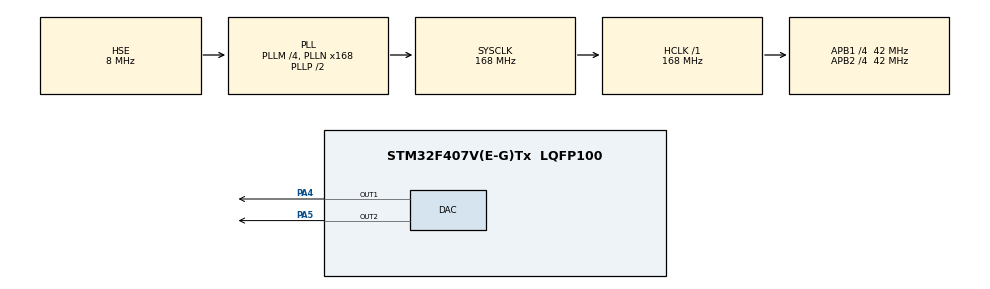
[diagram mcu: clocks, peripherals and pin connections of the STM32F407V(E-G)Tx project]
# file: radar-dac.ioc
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DAC.DAC_Trigger=DAC_TRIGGER_T2_TRGO
DAC.DAC_Trigger2=DAC_TRIGGER_T4_TRGO
DAC.TriangleAmplitude2=DAC_TRIANGLEAMPLITUDE_4095
DAC.WaveGeneration2=TriangleWaveGeneration
Dma.DAC1.0.Direction=DMA_MEMORY_TO_PERIPH
Dma.DAC1.0.FIFOMode=DMA_FIFOMODE_DISABLE
Dma.DAC1.0.Instance=DMA1_Stream5
Dma.DAC1.0.MemDataAlignment=DMA_MDATAALIGN_HALFWORD
Dma.DAC1.0.MemInc=DMA_MINC_ENABLE
Dma.DAC1.0.Mode=DMA_CIRCULAR
Dma.DAC1.0.PeriphDataAlignment=DMA_PDATAALIGN_HALFWORD
Dma.DAC1.0.PeriphInc=DMA_PINC_DISABLE
Dma.DAC1.0.Priority=DMA_PRIORITY_LOW
Dma.DAC2.1.Direction=DMA_MEMORY_TO_PERIPH
Dma.DAC2.1.FIFOMode=DMA_FIFOMODE_DISABLE
Dma.DAC2.1.Instance=DMA1_Stream6
Dma.DAC2.1.MemDataAlignment=DMA_MDATAALIGN_HALFWORD
Dma.DAC2.1.MemInc=DMA_MINC_ENABLE
Dma.DAC2.1.Mode=DMA_CIRCULAR
Dma.DAC2.1.PeriphDataAlignment=DMA_PDATAALIGN_HALFWORD
Dma.DAC2.1.PeriphInc=DMA_PINC_DISABLE
Dma.DAC2.1.Priority=DMA_PRIORITY_LOW
Dma.Request0=DAC1
Dma.Request1=DAC2
Mcu.Family=STM32F4
Mcu.Name=STM32F407V(E-G)Tx
Mcu.Package=LQFP100
NVIC.DMA1_Stream5_IRQn=true\:0\:0\:false\:false\:true\:false\:true\:true
NVIC.DMA1_Stream6_IRQn=true\:0\:0\:false\:false\:true\:false\:true\:true
NVIC.PriorityGroup=NVIC_PRIORITYGROUP_0
PA4.Signal=COMP_DAC1_group
PA5.Signal=COMP_DAC2_group
PH0-OSC_IN.Mode=HSE-External-Oscillator
PH0-OSC_IN.Signal=RCC_OSC_IN
PH1-OSC_OUT.Mode=HSE-External-Oscillator
PH1-OSC_OUT.Signal=RCC_OSC_OUT
ProjectManager.HeapSize=0x200
ProjectManager.StackSize=0x400
ProjectManager.TargetToolchain=STM32CubeIDE
RCC.48MHZClocksFreq_Value=48000000
RCC.AHBFreq_Value=168000000
RCC.APB1CLKDivider=RCC_HCLK_DIV4
RCC.APB1Freq_Value=42000000
RCC.APB1TimFreq_Value=84000000
RCC.APB2CLKDivider=RCC_HCLK_DIV4
RCC.APB2Freq_Value=42000000
RCC.APB2TimFreq_Value=84000000
RCC.CortexFreq_Value=168000000
RCC.HCLKFreq_Value=168000000
RCC.HSE_VALUE=8000000
RCC.HSI_VALUE=16000000
RCC.LSE_VALUE=32768
RCC.PLLM=4
RCC.PLLN=168
RCC.PLLQ=7
RCC.PLLSourceVirtual=RCC_PLLSOURCE_HSE
RCC.SYSCLKFreq_VALUE=168000000
RCC.SYSCLKSource=RCC_SYSCLKSOURCE_PLLCLK
RCC.VCOOutputFreq_Value=336000000
SH.COMP_DAC1_group.0=DAC_OUT1,DAC_OUT1
SH.COMP_DAC2_group.0=DAC_OUT2,DAC_OUT2
TIM2.Period=100-1
TIM2.Prescaler=84-1
TIM2.TIM_MasterOutputTrigger=TIM_TRGO_UPDATE
TIM4.Period=10-1
TIM4.Prescaler=84-1
TIM4.TIM_MasterOutputTrigger=TIM_TRGO_UPDATE
VP_TIM2_VS_ClockSourceINT.Mode=Internal
VP_TIM4_VS_ClockSourceINT.Mode=Internal
board=STM32F407G-DISC1

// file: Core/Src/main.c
/* USER CODE BEGIN Header */
/**
  ******************************************************************************
  * @file           : main.c
  * @brief          : Main program body
  ******************************************************************************
  * @attention
  *
  * Copyright (c) 2024 STMicroelectronics.
  * All rights reserved.
  *
  * This software is licensed under terms that can be found in the LICENSE file
  * in the root directory of this software component.
  * If no LICENSE file comes with this software, it is provided AS-IS.
  *
  ******************************************************************************
  */
/* USER CODE END Header */
#include "main.h"
#include "math.h"

DAC_HandleTypeDef hdac;
DMA_HandleTypeDef hdma_dac1;

TIM_HandleTypeDef htim2;
TIM_HandleTypeDef htim4;

void SystemClock_Config(void);
static void MX_GPIO_Init(void);
static void MX_DMA_Init(void);
static void MX_DAC_Init(void);
static void MX_TIM2_Init(void);
static void MX_TIM4_Init(void);

/* USER CODE BEGIN 0 */

float value = 0.2;
uint32_t var;
uint32_t sine_val[100];

#define PI 3.14159265358979323846

void calcsin ()
{
	for (int i=0; i<100; i++)
	{
		sine_val[i] = ((sin(i*2*PI/100) + 1)*(4096/2));
	}
}

/* USER CODE END 0 */

int main(void)
{

  /* MCU Configuration--------------------------------------------------------*/

  /* Reset of all peripherals, Initializes the Flash interface and the Systick. */
  HAL_Init();

  /* Configure the system clock */
  SystemClock_Config();

  /* Initialize all configured peripherals */
  MX_GPIO_Init();
  MX_DMA_Init();
  MX_DAC_Init();
  MX_TIM2_Init();
  MX_TIM4_Init();
  /* USER CODE BEGIN 2 */

  HAL_TIM_Base_Start(&htim4);
  HAL_DACEx_TriangleWaveGenerate(&hdac, DAC1_CHANNEL_2, DAC_TRIANGLEAMPLITUDE_2047);
  HAL_DAC_Start(&hdac, DAC1_CHANNEL_2);
  /* USER CODE END 2 */

  /* Infinite loop */
  while (1)
  {
	  HAL_TIM_Base_Start(&htim2);
	  calcsin();
	  HAL_DAC_Start_DMA(&hdac, DAC1_CHANNEL_1, sine_val, 100, DAC_ALIGN_12B_R);
  }
}

void SystemClock_Config(void)
{
  RCC_OscInitTypeDef RCC_OscInitStruct = {0};
  RCC_ClkInitTypeDef RCC_ClkInitStruct = {0};

  /** Configure the main internal regulator output voltage
  */
  __HAL_RCC_PWR_CLK_ENABLE();
  __HAL_PWR_VOLTAGESCALING_CONFIG(PWR_REGULATOR_VOLTAGE_SCALE1);

  /** Initializes the RCC Oscillators according to the specified parameters
  * in the RCC_OscInitTypeDef structure.
  */
  RCC_OscInitStruct.OscillatorType = RCC_OSCILLATORTYPE_HSE;
  RCC_OscInitStruct.HSEState = RCC_HSE_ON;
  RCC_OscInitStruct.PLL.PLLState = RCC_PLL_ON;
  RCC_OscInitStruct.PLL.PLLSource = RCC_PLLSOURCE_HSE;
  RCC_OscInitStruct.PLL.PLLM = 4;
  RCC_OscInitStruct.PLL.PLLN = 168;
  RCC_OscInitStruct.PLL.PLLP = RCC_PLLP_DIV2;
  RCC_OscInitStruct.PLL.PLLQ = 7;
  if (HAL_RCC_OscConfig(&RCC_OscInitStruct) != HAL_OK)
  {
    Error_Handler();
  }

  /** Initializes the CPU, AHB and APB buses clocks
  */
  RCC_ClkInitStruct.ClockType = RCC_CLOCKTYPE_HCLK|RCC_CLOCKTYPE_SYSCLK
                              |RCC_CLOCKTYPE_PCLK1|RCC_CLOCKTYPE_PCLK2;
  RCC_ClkInitStruct.SYSCLKSource = RCC_SYSCLKSOURCE_PLLCLK;
  RCC_ClkInitStruct.AHBCLKDivider = RCC_SYSCLK_DIV1;
  RCC_ClkInitStruct.APB1CLKDivider = RCC_HCLK_DIV4;
  RCC_ClkInitStruct.APB2CLKDivider = RCC_HCLK_DIV4;

  if (HAL_RCC_ClockConfig(&RCC_ClkInitStruct, FLASH_LATENCY_5) != HAL_OK)
  {
    Error_Handler();
  }
}

static void MX_DAC_Init(void)
{

  DAC_ChannelConfTypeDef sConfig = {0};

  /** DAC Initialization
  */
  hdac.Instance = DAC;
  if (HAL_DAC_Init(&hdac) != HAL_OK)
  {
    Error_Handler();
  }

  /** DAC channel OUT1 config
  */
  sConfig.DAC_Trigger = DAC_TRIGGER_T2_TRGO;
  sConfig.DAC_OutputBuffer = DAC_OUTPUTBUFFER_ENABLE;
  if (HAL_DAC_ConfigChannel(&hdac, &sConfig, DAC_CHANNEL_1) != HAL_OK)
  {
    Error_Handler();
  }

  /** DAC channel OUT2 config
  */
  sConfig.DAC_Trigger = DAC_TRIGGER_T4_TRGO;
  if (HAL_DAC_ConfigChannel(&hdac, &sConfig, DAC_CHANNEL_2) != HAL_OK)
  {
    Error_Handler();
  }

  /** Configure Triangle wave generation on DAC OUT2
  */
  if (HAL_DACEx_TriangleWaveGenerate(&hdac, DAC_CHANNEL_2, DAC_TRIANGLEAMPLITUDE_15) != HAL_OK)
  {
    Error_Handler();
  }

}

static void MX_TIM2_Init(void)
{

  TIM_ClockConfigTypeDef sClockSourceConfig = {0};
  TIM_MasterConfigTypeDef sMasterConfig = {0};

  htim2.Instance = TIM2;
  htim2.Init.Prescaler = 84-1;
  htim2.Init.CounterMode = TIM_COUNTERMODE_UP;
  htim2.Init.Period = 100-1;
  htim2.Init.ClockDivision = TIM_CLOCKDIVISION_DIV1;
  htim2.Init.AutoReloadPreload = TIM_AUTORELOAD_PRELOAD_DISABLE;
  if (HAL_TIM_Base_Init(&htim2) != HAL_OK)
  {
    Error_Handler();
  }
  sClockSourceConfig.ClockSource = TIM_CLOCKSOURCE_INTERNAL;
  if (HAL_TIM_ConfigClockSource(&htim2, &sClockSourceConfig) != HAL_OK)
  {
    Error_Handler();
  }
  sMasterConfig.MasterOutputTrigger = TIM_TRGO_UPDATE;
  sMasterConfig.MasterSlaveMode = TIM_MASTERSLAVEMODE_DISABLE;
  if (HAL_TIMEx_MasterConfigSynchronization(&htim2, &sMasterConfig) != HAL_OK)
  {
    Error_Handler();
  }

}

static void MX_TIM4_Init(void)
{

  TIM_ClockConfigTypeDef sClockSourceConfig = {0};
  TIM_MasterConfigTypeDef sMasterConfig = {0};

  htim4.Instance = TIM4;
  htim4.Init.Prescaler = 84-1;
  htim4.Init.CounterMode = TIM_COUNTERMODE_UP;
  htim4.Init.Period = 65535;
  htim4.Init.ClockDivision = TIM_CLOCKDIVISION_DIV1;
  htim4.Init.AutoReloadPreload = TIM_AUTORELOAD_PRELOAD_DISABLE;
  if (HAL_TIM_Base_Init(&htim4) != HAL_OK)
  {
    Error_Handler();
  }
  sClockSourceConfig.ClockSource = TIM_CLOCKSOURCE_INTERNAL;
  if (HAL_TIM_ConfigClockSource(&htim4, &sClockSourceConfig) != HAL_OK)
  {
    Error_Handler();
  }
  sMasterConfig.MasterOutputTrigger = TIM_TRGO_RESET;
  sMasterConfig.MasterSlaveMode = TIM_MASTERSLAVEMODE_DISABLE;
  if (HAL_TIMEx_MasterConfigSynchronization(&htim4, &sMasterConfig) != HAL_OK)
  {
    Error_Handler();
  }

}

static void MX_DMA_Init(void)
{

  /* DMA controller clock enable */
  __HAL_RCC_DMA1_CLK_ENABLE();

  /* DMA interrupt init */
  /* DMA1_Stream5_IRQn interrupt configuration */
  HAL_NVIC_SetPriority(DMA1_Stream5_IRQn, 0, 0);
  HAL_NVIC_EnableIRQ(DMA1_Stream5_IRQn);

}

static void MX_GPIO_Init(void)
{

  /* GPIO Ports Clock Enable */
  __HAL_RCC_GPIOH_CLK_ENABLE();
  __HAL_RCC_GPIOA_CLK_ENABLE();

}

void Error_Handler(void)
{
  __disable_irq();
  while (1)
  {
  }
}
